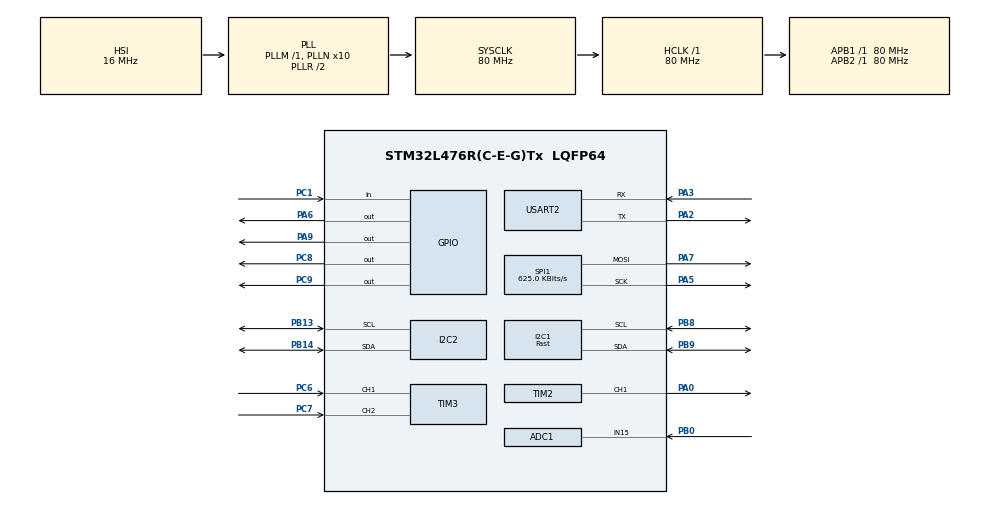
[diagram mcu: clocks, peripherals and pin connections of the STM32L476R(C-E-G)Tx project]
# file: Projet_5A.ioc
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ADC1.Channel-1\#ChannelRegularConversion=ADC_CHANNEL_15
ADC1.NbrOfConversionFlag=1
ADC1.OffsetNumber-1\#ChannelRegularConversion=ADC_OFFSET_NONE
ADC1.Rank-1\#ChannelRegularConversion=1
ADC1.SamplingTime-1\#ChannelRegularConversion=ADC_SAMPLETIME_2CYCLES_5
ADC1.master=1
I2C1.CustomTiming=Disabled
I2C1.I2C_Speed_Mode=I2C_Fast
I2C1.Speed=400
I2C1.Timing=0x00702991
I2C2.CustomTiming=Disabled
I2C2.Speed=10
I2C2.Timing=0xF010F3FE
Mcu.Family=STM32L4
Mcu.Name=STM32L476R(C-E-G)Tx
Mcu.Package=LQFP64
NVIC.PriorityGroup=NVIC_PRIORITYGROUP_4
NVIC.TIM5_IRQn=true\:0\:0\:false\:false\:true\:true\:true
PA0.Signal=S_TIM2_CH1
PA2.Mode=Asynchronous
PA2.Signal=USART2_TX
PA3.Mode=Asynchronous
PA3.Signal=USART2_RX
PA5.Mode=TX_Only_Simplex_Unidirect_Master
PA5.Signal=SPI1_SCK
PA6.Signal=GPIO_Output
PA7.Mode=TX_Only_Simplex_Unidirect_Master
PA7.Signal=SPI1_MOSI
PA9.Signal=GPIO_Output
PB0.Signal=ADCx_IN15
PB13.Mode=I2C
PB13.Signal=I2C2_SCL
PB14.Mode=I2C
PB14.Signal=I2C2_SDA
PB8.Mode=I2C
PB8.Signal=I2C1_SCL
PB9.Mode=I2C
PB9.Signal=I2C1_SDA
PC1.Signal=GPIO_Input
PC6.Signal=S_TIM3_CH1
PC7.Signal=S_TIM3_CH2
PC8.Signal=GPIO_Output
PC9.Signal=GPIO_Output
ProjectManager.HeapSize=0x200
ProjectManager.StackSize=0x400
ProjectManager.TargetToolchain=STM32CubeIDE
RCC.ADCFreq_Value=64000000
RCC.AHBFreq_Value=80000000
RCC.APB1Freq_Value=80000000
RCC.APB1TimFreq_Value=80000000
RCC.APB2Freq_Value=80000000
RCC.APB2TimFreq_Value=80000000
RCC.CortexFreq_Value=80000000
RCC.HCLKFreq_Value=80000000
RCC.HSE_VALUE=8000000
RCC.HSI_VALUE=16000000
RCC.LSE_VALUE=32768
RCC.MSI_VALUE=4000000
RCC.PLLN=10
RCC.PLLSourceVirtual=RCC_PLLSOURCE_HSI
RCC.SYSCLKFreq_VALUE=80000000
RCC.SYSCLKSource=RCC_SYSCLKSOURCE_PLLCLK
RCC.USBFreq_Value=64000000
RCC.VCOOutputFreq_Value=160000000
SH.ADCx_IN15.0=ADC1_IN15,IN15-Single-Ended
SH.S_TIM2_CH1.0=TIM2_CH1,PWM Generation1 CH1
SH.S_TIM3_CH1.0=TIM3_CH1,Encoder_Interface
SH.S_TIM3_CH2.0=TIM3_CH2,Encoder_Interface
SPI1.BaudRatePrescaler=SPI_BAUDRATEPRESCALER_128
SPI1.CalculateBaudRate=625.0 KBits/s
SPI1.DataSize=SPI_DATASIZE_8BIT
SPI1.Direction=SPI_DIRECTION_2LINES
SPI1.Mode=SPI_MODE_MASTER
SPI1.NSSPMode=SPI_NSS_PULSE_DISABLE
SPI1.VirtualType=VM_MASTER
TIM2.Channel-PWM\ Generation1\ CH1=TIM_CHANNEL_1
TIM2.Period=532
TIM5.Period=80000000
USART2.VirtualMode-Asynchronous=VM_ASYNC
VP_TIM5_VS_ClockSourceINT.Mode=Internal
board=custom

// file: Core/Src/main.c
/* USER CODE BEGIN Header */
/**
  ******************************************************************************
  * @file           : main.c
  * @brief          : Main program body
  ******************************************************************************
  * @attention
  *
  * <h2><center>&copy; Copyright (c) 2021 STMicroelectronics.
  * All rights reserved.</center></h2>
  *
  * This software component is licensed by ST under BSD 3-Clause license,
  * the "License"; You may not use this file except in compliance with the
  * License. You may obtain a copy of the License at:
  *                        opensource.org/licenses/BSD-3-Clause
  *
  ******************************************************************************
  */
/* USER CODE END Header */
#include "main.h"

/* USER CODE BEGIN Includes */
#include "app.h"
/* USER CODE END Includes */

ADC_HandleTypeDef hadc1;

I2C_HandleTypeDef hi2c1;
I2C_HandleTypeDef hi2c2;

SPI_HandleTypeDef hspi1;

TIM_HandleTypeDef htim2;
TIM_HandleTypeDef htim3;
TIM_HandleTypeDef htim5;

UART_HandleTypeDef huart2;

void SystemClock_Config(void);
static void MX_GPIO_Init(void);
static void MX_I2C1_Init(void);
static void MX_SPI1_Init(void);
static void MX_TIM3_Init(void);
static void MX_TIM2_Init(void);
static void MX_USART2_UART_Init(void);
static void MX_I2C2_Init(void);
static void MX_ADC1_Init(void);
static void MX_TIM5_Init(void);

int main(void)
{

  /* MCU Configuration--------------------------------------------------------*/

  /* Reset of all peripherals, Initializes the Flash interface and the Systick. */
  HAL_Init();

  /* Configure the system clock */
  SystemClock_Config();

  /* Initialize all configured peripherals */
  MX_GPIO_Init();
  MX_I2C1_Init();
  MX_SPI1_Init();
  MX_TIM3_Init();
  MX_TIM2_Init();
  MX_USART2_UART_Init();
  MX_I2C2_Init();
  MX_ADC1_Init();
  MX_TIM5_Init();

  /* Infinite loop */
  /* USER CODE BEGIN WHILE */
  My_app(); // never return
  while (1)
  {
    /* USER CODE END WHILE */

  }
}

void SystemClock_Config(void)
{
  RCC_OscInitTypeDef RCC_OscInitStruct = {0};
  RCC_ClkInitTypeDef RCC_ClkInitStruct = {0};

  /** Configure the main internal regulator output voltage
  */
  if (HAL_PWREx_ControlVoltageScaling(PWR_REGULATOR_VOLTAGE_SCALE1) != HAL_OK)
  {
    Error_Handler();
  }
  /** Initializes the RCC Oscillators according to the specified parameters
  * in the RCC_OscInitTypeDef structure.
  */
  RCC_OscInitStruct.OscillatorType = RCC_OSCILLATORTYPE_HSI;
  RCC_OscInitStruct.HSIState = RCC_HSI_ON;
  RCC_OscInitStruct.HSICalibrationValue = RCC_HSICALIBRATION_DEFAULT;
  RCC_OscInitStruct.PLL.PLLState = RCC_PLL_ON;
  RCC_OscInitStruct.PLL.PLLSource = RCC_PLLSOURCE_HSI;
  RCC_OscInitStruct.PLL.PLLM = 1;
  RCC_OscInitStruct.PLL.PLLN = 10;
  RCC_OscInitStruct.PLL.PLLP = RCC_PLLP_DIV7;
  RCC_OscInitStruct.PLL.PLLQ = RCC_PLLQ_DIV2;
  RCC_OscInitStruct.PLL.PLLR = RCC_PLLR_DIV2;
  if (HAL_RCC_OscConfig(&RCC_OscInitStruct) != HAL_OK)
  {
    Error_Handler();
  }
  /** Initializes the CPU, AHB and APB buses clocks
  */
  RCC_ClkInitStruct.ClockType = RCC_CLOCKTYPE_HCLK|RCC_CLOCKTYPE_SYSCLK
                              |RCC_CLOCKTYPE_PCLK1|RCC_CLOCKTYPE_PCLK2;
  RCC_ClkInitStruct.SYSCLKSource = RCC_SYSCLKSOURCE_PLLCLK;
  RCC_ClkInitStruct.AHBCLKDivider = RCC_SYSCLK_DIV1;
  RCC_ClkInitStruct.APB1CLKDivider = RCC_HCLK_DIV1;
  RCC_ClkInitStruct.APB2CLKDivider = RCC_HCLK_DIV1;

  if (HAL_RCC_ClockConfig(&RCC_ClkInitStruct, FLASH_LATENCY_4) != HAL_OK)
  {
    Error_Handler();
  }
}

static void MX_ADC1_Init(void)
{

  ADC_MultiModeTypeDef multimode = {0};
  ADC_ChannelConfTypeDef sConfig = {0};

  /** Common config
  */
  hadc1.Instance = ADC1;
  hadc1.Init.ClockPrescaler = ADC_CLOCK_ASYNC_DIV1;
  hadc1.Init.Resolution = ADC_RESOLUTION_12B;
  hadc1.Init.DataAlign = ADC_DATAALIGN_RIGHT;
  hadc1.Init.ScanConvMode = ADC_SCAN_DISABLE;
  hadc1.Init.EOCSelection = ADC_EOC_SINGLE_CONV;
  hadc1.Init.LowPowerAutoWait = DISABLE;
  hadc1.Init.ContinuousConvMode = DISABLE;
  hadc1.Init.NbrOfConversion = 1;
  hadc1.Init.DiscontinuousConvMode = DISABLE;
  hadc1.Init.ExternalTrigConv = ADC_SOFTWARE_START;
  hadc1.Init.ExternalTrigConvEdge = ADC_EXTERNALTRIGCONVEDGE_NONE;
  hadc1.Init.DMAContinuousRequests = DISABLE;
  hadc1.Init.Overrun = ADC_OVR_DATA_PRESERVED;
  hadc1.Init.OversamplingMode = DISABLE;
  if (HAL_ADC_Init(&hadc1) != HAL_OK)
  {
    Error_Handler();
  }
  /** Configure the ADC multi-mode
  */
  multimode.Mode = ADC_MODE_INDEPENDENT;
  if (HAL_ADCEx_MultiModeConfigChannel(&hadc1, &multimode) != HAL_OK)
  {
    Error_Handler();
  }
  /** Configure Regular Channel
  */
  sConfig.Channel = ADC_CHANNEL_15;
  sConfig.Rank = ADC_REGULAR_RANK_1;
  sConfig.SamplingTime = ADC_SAMPLETIME_2CYCLES_5;
  sConfig.SingleDiff = ADC_SINGLE_ENDED;
  sConfig.OffsetNumber = ADC_OFFSET_NONE;
  sConfig.Offset = 0;
  if (HAL_ADC_ConfigChannel(&hadc1, &sConfig) != HAL_OK)
  {
    Error_Handler();
  }

}

static void MX_I2C1_Init(void)
{

  hi2c1.Instance = I2C1;
  hi2c1.Init.Timing = 0x00702991;
  hi2c1.Init.OwnAddress1 = 0;
  hi2c1.Init.AddressingMode = I2C_ADDRESSINGMODE_7BIT;
  hi2c1.Init.DualAddressMode = I2C_DUALADDRESS_DISABLE;
  hi2c1.Init.OwnAddress2 = 0;
  hi2c1.Init.OwnAddress2Masks = I2C_OA2_NOMASK;
  hi2c1.Init.GeneralCallMode = I2C_GENERALCALL_DISABLE;
  hi2c1.Init.NoStretchMode = I2C_NOSTRETCH_DISABLE;
  if (HAL_I2C_Init(&hi2c1) != HAL_OK)
  {
    Error_Handler();
  }
  /** Configure Analogue filter
  */
  if (HAL_I2CEx_ConfigAnalogFilter(&hi2c1, I2C_ANALOGFILTER_ENABLE) != HAL_OK)
  {
    Error_Handler();
  }
  /** Configure Digital filter
  */
  if (HAL_I2CEx_ConfigDigitalFilter(&hi2c1, 0) != HAL_OK)
  {
    Error_Handler();
  }

}

static void MX_I2C2_Init(void)
{

  hi2c2.Instance = I2C2;
  hi2c2.Init.Timing = 0xF010F3FE;
  hi2c2.Init.OwnAddress1 = 0;
  hi2c2.Init.AddressingMode = I2C_ADDRESSINGMODE_7BIT;
  hi2c2.Init.DualAddressMode = I2C_DUALADDRESS_DISABLE;
  hi2c2.Init.OwnAddress2 = 0;
  hi2c2.Init.OwnAddress2Masks = I2C_OA2_NOMASK;
  hi2c2.Init.GeneralCallMode = I2C_GENERALCALL_DISABLE;
  hi2c2.Init.NoStretchMode = I2C_NOSTRETCH_DISABLE;
  if (HAL_I2C_Init(&hi2c2) != HAL_OK)
  {
    Error_Handler();
  }
  /** Configure Analogue filter
  */
  if (HAL_I2CEx_ConfigAnalogFilter(&hi2c2, I2C_ANALOGFILTER_ENABLE) != HAL_OK)
  {
    Error_Handler();
  }
  /** Configure Digital filter
  */
  if (HAL_I2CEx_ConfigDigitalFilter(&hi2c2, 0) != HAL_OK)
  {
    Error_Handler();
  }

}

static void MX_SPI1_Init(void)
{

  /* SPI1 parameter configuration*/
  hspi1.Instance = SPI1;
  hspi1.Init.Mode = SPI_MODE_MASTER;
  hspi1.Init.Direction = SPI_DIRECTION_2LINES;
  hspi1.Init.DataSize = SPI_DATASIZE_8BIT;
  hspi1.Init.CLKPolarity = SPI_POLARITY_LOW;
  hspi1.Init.CLKPhase = SPI_PHASE_1EDGE;
  hspi1.Init.NSS = SPI_NSS_SOFT;
  hspi1.Init.BaudRatePrescaler = SPI_BAUDRATEPRESCALER_128;
  hspi1.Init.FirstBit = SPI_FIRSTBIT_MSB;
  hspi1.Init.TIMode = SPI_TIMODE_DISABLE;
  hspi1.Init.CRCCalculation = SPI_CRCCALCULATION_DISABLE;
  hspi1.Init.CRCPolynomial = 7;
  hspi1.Init.CRCLength = SPI_CRC_LENGTH_DATASIZE;
  hspi1.Init.NSSPMode = SPI_NSS_PULSE_DISABLE;
  if (HAL_SPI_Init(&hspi1) != HAL_OK)
  {
    Error_Handler();
  }

}

static void MX_TIM2_Init(void)
{

  TIM_MasterConfigTypeDef sMasterConfig = {0};
  TIM_OC_InitTypeDef sConfigOC = {0};

  htim2.Instance = TIM2;
  htim2.Init.Prescaler = 0;
  htim2.Init.CounterMode = TIM_COUNTERMODE_UP;
  htim2.Init.Period = 532;
  htim2.Init.ClockDivision = TIM_CLOCKDIVISION_DIV1;
  htim2.Init.AutoReloadPreload = TIM_AUTORELOAD_PRELOAD_DISABLE;
  if (HAL_TIM_PWM_Init(&htim2) != HAL_OK)
  {
    Error_Handler();
  }
  sMasterConfig.MasterOutputTrigger = TIM_TRGO_RESET;
  sMasterConfig.MasterSlaveMode = TIM_MASTERSLAVEMODE_DISABLE;
  if (HAL_TIMEx_MasterConfigSynchronization(&htim2, &sMasterConfig) != HAL_OK)
  {
    Error_Handler();
  }
  sConfigOC.OCMode = TIM_OCMODE_PWM1;
  sConfigOC.Pulse = 0;
  sConfigOC.OCPolarity = TIM_OCPOLARITY_HIGH;
  sConfigOC.OCFastMode = TIM_OCFAST_DISABLE;
  if (HAL_TIM_PWM_ConfigChannel(&htim2, &sConfigOC, TIM_CHANNEL_1) != HAL_OK)
  {
    Error_Handler();
  }
  HAL_TIM_MspPostInit(&htim2);

}

static void MX_TIM3_Init(void)
{

  TIM_Encoder_InitTypeDef sConfig = {0};
  TIM_MasterConfigTypeDef sMasterConfig = {0};

  htim3.Instance = TIM3;
  htim3.Init.Prescaler = 0;
  htim3.Init.CounterMode = TIM_COUNTERMODE_UP;
  htim3.Init.Period = 65535;
  htim3.Init.ClockDivision = TIM_CLOCKDIVISION_DIV1;
  htim3.Init.AutoReloadPreload = TIM_AUTORELOAD_PRELOAD_DISABLE;
  sConfig.EncoderMode = TIM_ENCODERMODE_TI1;
  sConfig.IC1Polarity = TIM_ICPOLARITY_RISING;
  sConfig.IC1Selection = TIM_ICSELECTION_DIRECTTI;
  sConfig.IC1Prescaler = TIM_ICPSC_DIV1;
  sConfig.IC1Filter = 0;
  sConfig.IC2Polarity = TIM_ICPOLARITY_RISING;
  sConfig.IC2Selection = TIM_ICSELECTION_DIRECTTI;
  sConfig.IC2Prescaler = TIM_ICPSC_DIV1;
  sConfig.IC2Filter = 0;
  if (HAL_TIM_Encoder_Init(&htim3, &sConfig) != HAL_OK)
  {
    Error_Handler();
  }
  sMasterConfig.MasterOutputTrigger = TIM_TRGO_RESET;
  sMasterConfig.MasterSlaveMode = TIM_MASTERSLAVEMODE_DISABLE;
  if (HAL_TIMEx_MasterConfigSynchronization(&htim3, &sMasterConfig) != HAL_OK)
  {
    Error_Handler();
  }

}

static void MX_TIM5_Init(void)
{

  TIM_ClockConfigTypeDef sClockSourceConfig = {0};
  TIM_MasterConfigTypeDef sMasterConfig = {0};

  htim5.Instance = TIM5;
  htim5.Init.Prescaler = 0;
  htim5.Init.CounterMode = TIM_COUNTERMODE_UP;
  htim5.Init.Period = 80000000;
  htim5.Init.ClockDivision = TIM_CLOCKDIVISION_DIV1;
  htim5.Init.AutoReloadPreload = TIM_AUTORELOAD_PRELOAD_DISABLE;
  if (HAL_TIM_Base_Init(&htim5) != HAL_OK)
  {
    Error_Handler();
  }
  sClockSourceConfig.ClockSource = TIM_CLOCKSOURCE_INTERNAL;
  if (HAL_TIM_ConfigClockSource(&htim5, &sClockSourceConfig) != HAL_OK)
  {
    Error_Handler();
  }
  sMasterConfig.MasterOutputTrigger = TIM_TRGO_RESET;
  sMasterConfig.MasterSlaveMode = TIM_MASTERSLAVEMODE_DISABLE;
  if (HAL_TIMEx_MasterConfigSynchronization(&htim5, &sMasterConfig) != HAL_OK)
  {
    Error_Handler();
  }

}

static void MX_USART2_UART_Init(void)
{

  huart2.Instance = USART2;
  huart2.Init.BaudRate = 115200;
  huart2.Init.WordLength = UART_WORDLENGTH_8B;
  huart2.Init.StopBits = UART_STOPBITS_1;
  huart2.Init.Parity = UART_PARITY_NONE;
  huart2.Init.Mode = UART_MODE_TX_RX;
  huart2.Init.HwFlowCtl = UART_HWCONTROL_NONE;
  huart2.Init.OverSampling = UART_OVERSAMPLING_16;
  huart2.Init.OneBitSampling = UART_ONE_BIT_SAMPLE_DISABLE;
  huart2.AdvancedInit.AdvFeatureInit = UART_ADVFEATURE_NO_INIT;
  if (HAL_UART_Init(&huart2) != HAL_OK)
  {
    Error_Handler();
  }

}

static void MX_GPIO_Init(void)
{
  GPIO_InitTypeDef GPIO_InitStruct = {0};

  /* GPIO Ports Clock Enable */
  __HAL_RCC_GPIOC_CLK_ENABLE();
  __HAL_RCC_GPIOA_CLK_ENABLE();
  __HAL_RCC_GPIOB_CLK_ENABLE();

  /*Configure GPIO pin Output Level */
  HAL_GPIO_WritePin(GPIOA, GPIO_PIN_6|GPIO_PIN_9, GPIO_PIN_RESET);

  /*Configure GPIO pin Output Level */
  HAL_GPIO_WritePin(GPIOC, GPIO_PIN_8|GPIO_PIN_9, GPIO_PIN_RESET);

  /*Configure GPIO pin : PC1 */
  GPIO_InitStruct.Pin = GPIO_PIN_1;
  GPIO_InitStruct.Mode = GPIO_MODE_INPUT;
  GPIO_InitStruct.Pull = GPIO_NOPULL;
  HAL_GPIO_Init(GPIOC, &GPIO_InitStruct);

  /*Configure GPIO pins : PA6 PA9 */
  GPIO_InitStruct.Pin = GPIO_PIN_6|GPIO_PIN_9;
  GPIO_InitStruct.Mode = GPIO_MODE_OUTPUT_PP;
  GPIO_InitStruct.Pull = GPIO_NOPULL;
  GPIO_InitStruct.Speed = GPIO_SPEED_FREQ_LOW;
  HAL_GPIO_Init(GPIOA, &GPIO_InitStruct);

  /*Configure GPIO pins : PC8 PC9 */
  GPIO_InitStruct.Pin = GPIO_PIN_8|GPIO_PIN_9;
  GPIO_InitStruct.Mode = GPIO_MODE_OUTPUT_PP;
  GPIO_InitStruct.Pull = GPIO_NOPULL;
  GPIO_InitStruct.Speed = GPIO_SPEED_FREQ_LOW;
  HAL_GPIO_Init(GPIOC, &GPIO_InitStruct);

}

void Error_Handler(void)
{
  __disable_irq();
  while (1)
  {
  }
}

/************************ (C) COPYRIGHT STMicroelectronics *****END OF FILE****/
